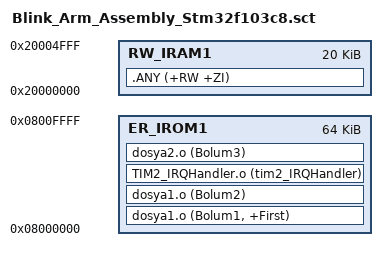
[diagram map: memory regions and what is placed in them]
; *************************************************************
; *** Scatter-Loading Description File generated by uVision ***
; *************************************************************

LR_IROM1 0x08000000 0x00010000  {    ; load region size_region
  ER_IROM1 0x08000000 0x00010000  {  ; load address = execution address
   dosya1.o (Bolum1, +First)
   dosya1.o (Bolum2)
   TIM2_IRQHandler.o (tim2_IRQHandler)
   dosya2.o (Bolum3)
  }
  RW_IRAM1 0x20000000 0x00005000  {  ; RW data
   .ANY (+RW +ZI)
  }
}

